# EFR32MG21A020F1024IM32 register map
Vendor: Silicon Labs; Series: EFR32; File version: B
Registers are 32-bit, read-write, reset 0x0 unless marked. A register's access mark holds for its fields unless they carry their own. Offsets are from the block's base; [hi:lo] are bit positions; {n}, {i} and the like mark numbered series.

## BUFC_S — BUFC_S Registers
Base 0x44004000
Same registers: BUFC_NS 0x54004000
0x00 IPVERSION ro
0x04 EN
  [0] EN — Enable peripheral clock to this module
{0x8+0x30*i} BUF{i}_CTRL (i=0..3)
  [2:0] SIZE — Buffer Size
    0=Sets Buffer size to 64 bytes; 1=Sets Buffer size to 128 bytes; 2=Sets Buffer size to 256 bytes; 3=Sets Buffer size to 512 bytes; 4=Sets Buffer size to 1024 bytes; 5=Sets Buffer size to 2048 bytes; 6=Sets Buffer size to 4096 bytes
{0xC+0x30*i} BUF{i}_ADDR (i=0..3)
  [23:0] ADDR — Buffer Address
{0x10+0x30*i} BUF{i}_WRITEOFFSET (i=0..3)
  [12:0] WRITEOFFSET
{0x14+0x30*i} BUF{i}_READOFFSET (i=0..3)
  [12:0] READOFFSET
{0x1C+0x30*i} BUF{i}_READDATA ro (i=0..3)
  [7:0] READDATA — Buffer Read Data
{0x20+0x30*i} BUF{i}_WRITEDATA wo (i=0..3)
  [7:0] WRITEDATA — Buffer Write Data
{0x24+0x30*i} BUF{i}_XWRITE wo (i=0..3)
  [7:0] XORWRITEDATA — Buffer XOR Write Data
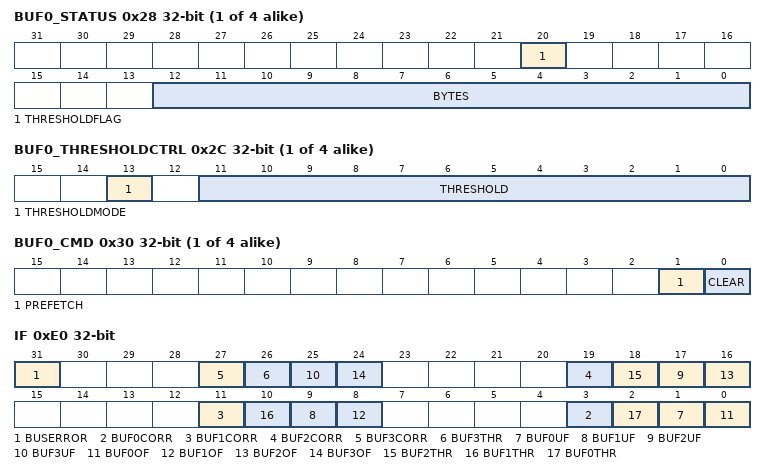
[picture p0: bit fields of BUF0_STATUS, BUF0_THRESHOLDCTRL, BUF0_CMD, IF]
{0x28+0x30*i} BUF{i}_STATUS ro (i=0..3)
  [20] THRESHOLDFLAG — Buffer Threshold Flag
  [12:0] BYTES — Number of Bytes in the Buffer
{0x2C+0x30*i} BUF{i}_THRESHOLDCTRL (i=0..3)
  [13] THRESHOLDMODE — Buffer Threshold Mode
    0=LARGER (THRESHOLDIF will be set if BYTES is larger than THRESHOLD); 1=LESSOREQUAL (THRESHOLDIF will be set if BYTES is less than or equal to THRESHOLD)
  [11:0] THRESHOLD — Buffer Threshold Value
{0x30+0x30*i} BUF{i}_CMD wo (i=0..3)
  [1] PREFETCH
  [0] CLEAR — Buffer Clear
{0x34+0x30*i} BUF{i}_FIFOASYNC wo (i=0..3)
  [0] RST — Reset ASYNC
0xE0 IF
  [31] BUSERROR
  [8n+3] BUF{n}CORR (n=0..3) — Buffer {n} Corrupt
  [26] BUF3THR — Buffer 3 Threshold Event
  [8n+1] BUF{n}UF (n=0..3) — Buffer {n} Underflow
  [8n] BUF{n}OF (n=0..3) — Buffer {n} Overflow
  [18] BUF2THR — Buffer 2 Threshold Event
  [10] BUF1THR — Buffer 2 Threshold Event
  [2] BUF0THR — Buffer 0 Threshold Event
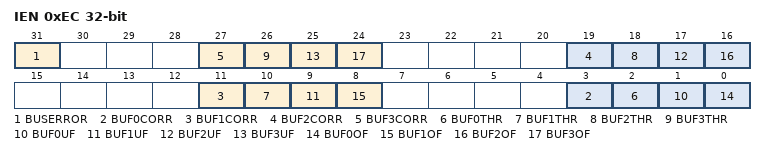
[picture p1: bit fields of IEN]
0xEC IEN
  [31] BUSERROR — BUSERROR Interrupt Enable
  [8n+3] BUF{n}CORR (n=0..3) — BUF{n}CORR Interrupt Enable
  [8n+2] BUF{n}THR (n=0..3) — BUF{n}THR Interrupt Enable
  [8n+1] BUF{n}UF (n=0..3) — BUF{n}UF Interrupt Enable
  [8n] BUF{n}OF (n=0..3) — BUF{n}OF Interrupt Enable
0xF0 RAMBASEADDR reset 0x20000000
  [31:16] RAMBASEADDR

## WDOG0_S — WDOG0_S Registers
Base 0x4A018000
Same registers: WDOG1_S 0x4A01C000, WDOG0_NS 0x5A018000, WDOG1_NS 0x5A01C000
0x00 IPVERSION ro
0x04 EN
  [0] EN — Module Enable
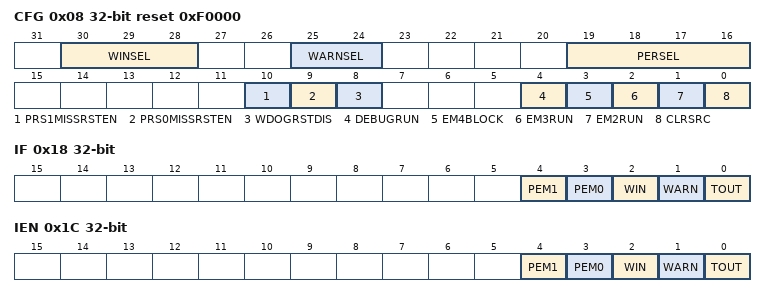
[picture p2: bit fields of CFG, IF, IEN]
0x08 CFG reset 0xF0000
  [30:28] WINSEL — WDOG Illegal Window Select
    0=DIS (Disabled.); 1=SEL1 (Window timeout is 12.5% of the Timeout.); 2=SEL2 (Window timeout is 25% of the Timeout.); 3=SEL3 (Window timeout is 37.5% of the Timeout.); 4=SEL4 (Window timeout is 50% of the Timeout.); 5=SEL5 (Window timeout is 62.5% of the Timeout.); 6=SEL6 (Window timeout is 75.5% of the Timeout.); 7=SEL7 (Window timeout is 87.5% of the Timeout.)
  [25:24] WARNSEL — WDOG Warning Period Select
    0=DIS (Disable); 1=SEL1 (Warning timeout is 25% of the Timeout.); 2=SEL2 (Warning timeout is 50% of the Timeout.); 3=SEL3 (Warning timeout is 75% of the Timeout.)
  [19:16] PERSEL — WDOG Timeout Period Select
    0=SEL0 (Timeout period of 9 wdog cycles); 1=SEL1 (Timeout period of 17 wdog cycles); 2=SEL2 (Timeout period of 33 wdog cycles); 3=SEL3 (Timeout period of 65 wdog cycles); 4=SEL4 (Timeout period of 129 wdog cycles); 5=SEL5 (Timeout period of 257 wdog cycles); 6=SEL6 (Timeout period of 513 wdog cycles); 7=SEL7 (Timeout period of 1k wdog cycles); 8=SEL8 (Timeout period of 2k wdog cycles); 9=SEL9 (Timeout period of 4k wdog cycles); 10=SEL10 (Timeout period of 8k wdog cycles); 11=SEL11 (Timeout period of 16k wdog cycles); 12=SEL12 (Timeout period of 32k wdog cycles); 13=SEL13 (Timeout period of 64k wdog cycles); 14=SEL14 (Timeout period of 128k wdog cycles); 15=SEL15 (Timeout period of 256k wdog cycles)
  [10] PRS1MISSRSTEN — PRS Src1 Missing Event WDOG Reset
  [9] PRS0MISSRSTEN — PRS Src0 Missing Event WDOG Reset
  [8] WDOGRSTDIS — WDOG Reset Disable
    0=EN (A timeout will cause a WDOG reset); 1=DIS (A timeout will not cause a WDOG reset)
  [4] DEBUGRUN — Debug Mode Run
    0=DISABLE (WDOG timer is frozen in debug mode); 1=ENABLE (WDOG timer is running in debug mode)
  [3] EM4BLOCK
    0=DISABLE (EM4 can be entered by software. See EMU for detailed description.); 1=ENABLE (EM4 cannot be entered by software.)
  [2] EM3RUN
    0=DISABLE (WDOG timer is frozen in EM3.); 1=ENABLE (WDOG timer is running in EM3.)
  [1] EM2RUN
    0=DISABLE (WDOG timer is frozen in EM2.); 1=ENABLE (WDOG timer is running in EM2.)
  [0] CLRSRC — WDOG Clear Source
    0=SW (A write to the clear bit will clear the WDOG counter); 1=PRSSRC0 (A rising edge on the PRS Source 0 will clear the WDOG counter)
0x0C CMD wo
  [0] CLEAR — WDOG Timer Clear
    0=UNCHANGED (WDOG timer is unchanged.); 1=CLEARED (WDOG timer is cleared to 0.)
0x14 STATUS ro
  [31] LOCK — WDOG Configuration Lock Status
    0=UNLOCKED (All WDOG lockable registers are unlocked.); 1=LOCKED (All WDOG lockable registers are locked.)
0x18 IF
  [4] PEM1 — PRS Src1 Event Missing Interrupt Flag
  [3] PEM0 — PRS Src0 Event Missing Interrupt Flag
  [2] WIN — WDOG Window Interrupt Flag
  [1] WARN — WDOG Warning Timeout Interrupt Flag
  [0] TOUT — WDOG Timeout Interrupt Flag
0x1C IEN
  [4] PEM1 — PRS Src1 Event Missing Interrupt Enable
  [3] PEM0 — PRS Src0 Event Missing Interrupt Enable
  [2] WIN — WDOG Window Interrupt Enable
  [1] WARN — WDOG Warning Timeout Interrupt Enable
  [0] TOUT — WDOG Timeout Interrupt Enable
0x20 LOCK wo reset 0xABE8
  [15:0] LOCKKEY — WDOG Configuration Lock
    0=LOCK (Lock WDOG lockable registers); 0xABE8=UNLOCK (Unlock WDOG lockable registers)
0x24 SYNCBUSY ro
  [0] CMD — Sync Busy for Cmd Register
